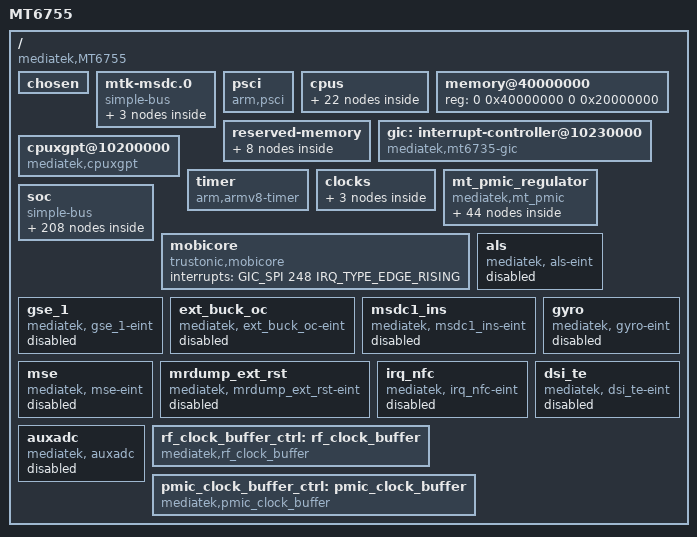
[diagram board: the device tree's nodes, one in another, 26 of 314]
/*
 * Mediatek's MT6755 SoC device tree source
 *
 * Copyright (c) 2013 MediaTek Co., Ltd.
 *              http://www.mediatek.com
 *
 */

#include <dt-bindings/clock/mt6755-clk.h>
#include <dt-bindings/interrupt-controller/arm-gic.h>
#include <dt-bindings/interrupt-controller/irq.h>
#include <dt-bindings/mmc/mt6755-msdc.h>
#include "mt6755-pinfunc.h"
/ {
	model = "MT6755";
	compatible = "mediatek,MT6755";
	interrupt-parent = <&gic>;
	#address-cells = <2>;
	#size-cells = <2>;

	/* chosen */
	chosen {
		bootargs = "console=tty0 console=ttyMT0,921600n1 root=/dev/ram initrd=0x44000000,0x4b434e loglevel=8";
	};

	/* Do not put any bus before mtk-msdc, because it should be mtk-msdc.0 for partition device node usage */
	mtk-msdc.0 {
		compatible = "simple-bus";
		#address-cells = <1>;
		#size-cells = <1>;
		ranges = <0 0 0 0xffffffff>;

		mmc0: msdc0@11230000 {
			compatible = "mediatek,mt6755-mmc";
			reg = <0x11230000 0x10000>;
			interrupts = <GIC_SPI 79 IRQ_TYPE_LEVEL_LOW>;
			clocks = <&infrasys INFRA_MSDC0>;
			clock-names = "MSDC0-CLOCK";
		};

		mmc1: msdc1@11240000 {
			compatible = "mediatek,mt6755-mmc";
			reg = <0x11240000 0x10000>;
			interrupts = <GIC_SPI 80 IRQ_TYPE_LEVEL_LOW>;
			clocks = <&infrasys INFRA_MSDC1>;
			clock-names = "MSDC1-CLOCK";
		};

		mmc2: msdc2@11250000 {
			compatible = "mediatek,mt6755-mmc";
			reg = <0x11250000 0x10000>;
			interrupts = <GIC_SPI 81 IRQ_TYPE_LEVEL_LOW>;
			clocks = <&infrasys INFRA_MSDC2>;
			clock-names = "MSDC2-CLOCK";
		};

		/*
		mmc3: msdc3@11260000 {
			compatible = "mediatek,mt6755-mmc";
			reg = <0x11260000 0x10000>;
			interrupts = <GIC_SPI 82 IRQ_TYPE_LEVEL_LOW>;
			clocks = <&infrasys INFRA_MSDC3>;
			clock-names = "MSDC3-CLOCK";
		};
*/
	};

	psci {
		compatible  = "arm,psci";
		method      = "smc";
		cpu_suspend = <0x84000001>;
		cpu_off     = <0x84000002>;
		cpu_on      = <0x84000003>;
		affinity_info = <0x84000004>;
	};

	cpus {
		#address-cells = <1>;
		#size-cells = <0>;

		cpu0: cpu@000 {
			device_type = "cpu";
			compatible = "arm,cortex-a53";
			reg = <0x000>;
			enable-method = "mt-boot";
			cpu-idle-states = <&cluster_sleep_0 &cluster_sleep_0 &cluster_sleep_0>,
					  <&cpu_sleep_0_0 &cpu_sleep_0_0 &cpu_sleep_0_0>;
			cpu-release-addr = <0x0 0x40000200>;
			clock-frequency = <1144000000>;
		};
		cpu1: cpu@001 {
			device_type = "cpu";
			compatible = "arm,cortex-a53";
			reg = <0x001>;
			enable-method = "mt-boot";
			cpu-idle-states = <&cluster_sleep_0 &cluster_sleep_0 &cluster_sleep_0>,
					  <&cpu_sleep_0_0 &cpu_sleep_0_0 &cpu_sleep_0_0>;
			cpu-release-addr = <0x0 0x40000200>;
			clock-frequency = <1144000000>;
		};

		cpu2: cpu@002 {
			device_type = "cpu";
			compatible = "arm,cortex-a53";
			reg = <0x002>;
			enable-method = "mt-boot";
			cpu-idle-states = <&cluster_sleep_0 &cluster_sleep_0 &cluster_sleep_0>,
					  <&cpu_sleep_0_0 &cpu_sleep_0_0 &cpu_sleep_0_0>;
			cpu-release-addr = <0x0 0x40000200>;
			clock-frequency = <1144000000>;
		};

		cpu3: cpu@003 {
			device_type = "cpu";
			compatible = "arm,cortex-a53";
			reg = <0x003>;
			enable-method = "mt-boot";
			cpu-idle-states = <&cluster_sleep_0 &cluster_sleep_0 &cluster_sleep_0>,
					  <&cpu_sleep_0_0 &cpu_sleep_0_0 &cpu_sleep_0_0>;
			cpu-release-addr = <0x0 0x40000200>;
			clock-frequency = <1144000000>;
		};

		cpu4: cpu@100 {
			device_type = "cpu";
			compatible = "arm,cortex-a53";
			reg = <0x100>;
			enable-method = "mt-boot";
			cpu-idle-states = <&cluster_sleep_0 &cluster_sleep_0 &cluster_sleep_0>,
					  <&cpu_sleep_0_0 &cpu_sleep_0_0 &cpu_sleep_0_0>;
			cpu-release-addr = <0x0 0x40000200>;
			clock-frequency = <1950000000>;
		};

		cpu5: cpu@101 {
			device_type = "cpu";
			compatible = "arm,cortex-a53";
			reg = <0x101>;
			enable-method = "mt-boot";
			cpu-idle-states = <&cluster_sleep_0 &cluster_sleep_0 &cluster_sleep_0>,
					  <&cpu_sleep_0_0 &cpu_sleep_0_0 &cpu_sleep_0_0>;
			cpu-release-addr = <0x0 0x40000200>;
			clock-frequency = <1950000000>;
		};

		cpu6: cpu@102 {
			device_type = "cpu";
			compatible = "arm,cortex-a53";
			reg = <0x102>;
			enable-method = "mt-boot";
			cpu-idle-states = <&cluster_sleep_0 &cluster_sleep_0 &cluster_sleep_0>,
					  <&cpu_sleep_0_0 &cpu_sleep_0_0 &cpu_sleep_0_0>;
			cpu-release-addr = <0x0 0x40000200>;
			clock-frequency = <1950000000>;
		};

		cpu7: cpu@103 {
			device_type = "cpu";
			compatible = "arm,cortex-a53";
			reg = <0x103>;
			enable-method = "mt-boot";
			cpu-idle-states = <&cluster_sleep_0 &cluster_sleep_0 &cluster_sleep_0>,
					  <&cpu_sleep_0_0 &cpu_sleep_0_0 &cpu_sleep_0_0>;
			cpu-release-addr = <0x0 0x40000200>;
			clock-frequency = <1950000000>;

		};

		cpu-map {
			cluster0 {
				core0 {
					cpu = <&cpu0>;
				};
				core1 {
					cpu = <&cpu1>;
				};
				core2 {
					cpu = <&cpu2>;
				};
				core3 {
					cpu = <&cpu3>;
				};
			};

			cluster1 {
				core0 {
					cpu = <&cpu4>;
				};
				core1 {
					cpu = <&cpu5>;
				};
				core2 {
					cpu = <&cpu6>;
				};
				core3 {
					cpu = <&cpu7>;
				};
			};
		};

		idle-states {
			entry-method = "arm,psci";

			cpu_sleep_0_0: cpu-sleep-0-0 {
				compatible = "arm,idle-state";
				arm,psci-suspend-param = <0x0010000>;
				entry-latency-us = <600>;
				exit-latency-us = <600>;
				min-residency-us = <1200>;
			};

			cluster_sleep_0: cluster-sleep-0 {
				compatible = "arm,idle-state";
				arm,psci-suspend-param = <0x1010000>;
				entry-latency-us = <800>;
				exit-latency-us = <1000>;
				min-residency-us = <2000>;
			};
		};
	};

	memory@40000000 {
		device_type = "memory";
		reg = <0 0x40000000 0 0x20000000>;
	};

	reserved-memory {
		#address-cells = <2>;
		#size-cells = <2>;
		ranges;

		/* reserve 192KB at DRAM start + 48MB */
		atf-reserved-memory@43000000 {
			compatible = "mediatek,mt6735-atf-reserved-memory",
				"mediatek,mt6735m-atf-reserved-memory",
				"mediatek,mt6753-atf-reserved-memory";
			no-map;
			reg = <0 0x43000000 0 0x30000>;
		};

		reserve-memory-ccci_md1 {
			compatible = "mediatek,reserve-memory-ccci_md1";
			no-map;
			size = <0 0xA100000>; /* md_size+smem_size */
			alignment = <0 0x2000000>;
			alloc-ranges = <0 0x40000000 0 0xC0000000>;
		};

		consys-reserve-memory {
			compatible = "mediatek,consys-reserve-memory";
			no-map;
			size = <0 0x100000>;
			alignment = <0 0x200000>;
		};

		ram_console-reserved-memory@44400000 {
			compatible = "mediatek,ram_console";
			reg = <0 0x44400000 0 0x10000>;
		};

		preloader-reserved-memory@44800000 {
			compatible = "mediatek,preloader";
			reg = <0 0x44800000 0 0x200000>;
		};

		lk-reserved-memory@46000000 {
			compatible = "mediatek,lk";
			reg = <0 0x46000000 0 0x900000>;
		};

		minirdump-reserved-memory@444f0000 {
			compatible = "mediatek, minirdump";
			reg = <0 0x444f0000 0 0x10000>;
		};

		pstore-reserved-memory@44410000 {
			compatible = "mediatek,pstore";
			reg = <0 0x44410000 0 0xe0000>;
		};

	};

	gic: interrupt-controller@10230000 {
		compatible = "mediatek,mt6735-gic";
		#interrupt-cells = <3>;
		#address-cells = <0>;
		interrupt-controller;
		reg = <0 0x10231000 0 0x1000>,
		      <0 0x10232000 0 0x1000>,
		      <0 0x10200620 0 0x1000>;
	};

	cpuxgpt@10200000 {
		compatible = "mediatek,cpuxgpt";
		reg = <0 0x10200000 0 0x1000>;
		interrupts = <GIC_SPI 64 IRQ_TYPE_LEVEL_HIGH>,
				<GIC_SPI 65 IRQ_TYPE_LEVEL_HIGH>,
				<GIC_SPI 66 IRQ_TYPE_LEVEL_HIGH>,
				<GIC_SPI 67 IRQ_TYPE_LEVEL_HIGH>,
				<GIC_SPI 68 IRQ_TYPE_LEVEL_HIGH>,
				<GIC_SPI 69 IRQ_TYPE_LEVEL_HIGH>,
				<GIC_SPI 70 IRQ_TYPE_LEVEL_HIGH>,
				<GIC_SPI 71 IRQ_TYPE_LEVEL_HIGH>;
	};

	timer {
		compatible = "arm,armv8-timer";
		interrupts = <GIC_PPI 13 IRQ_TYPE_LEVEL_LOW>,
				<GIC_PPI 14 IRQ_TYPE_LEVEL_LOW>,
				<GIC_PPI 11 IRQ_TYPE_LEVEL_LOW>,
				<GIC_PPI 10 IRQ_TYPE_LEVEL_LOW>;
		clock-frequency = <13000000>;
		};

	clocks {
		clk_null: clk_null {
			compatible = "fixed-clock";
			#clock-cells = <0>;
			clock-frequency = <0>;
		};

		clk26m: clk26m {
			compatible = "fixed-clock";
			#clock-cells = <0>;
			clock-frequency = <26000000>;
		};

		clk32k: clk32k {
			compatible = "fixed-clock";
			#clock-cells = <0>;
			clock-frequency = <32000>;
		};
	};

	mt_pmic_regulator {
		compatible = "mediatek,mt_pmic";
		/*reg = <0x01>*/
		buck_regulators {
			compatible = "mediatek,mt_pmic_buck_regulators";
			mt_pmic_vcore_buck_reg: buck_vcore {
				regulator-name = "vcore";
				regulator-min-microvolt = <600000>;
				regulator-max-microvolt = <1393750>;
				regulator-ramp-delay = <6250>;
				regulator-enable-ramp-delay = <180>;
			};
			mt_pmic_vgpu_buck_reg: buck_vgpu {
				regulator-name = "vgpu";
				regulator-min-microvolt = <600000>;
				regulator-max-microvolt = <1393750>;
				regulator-ramp-delay = <6250>;
				regulator-enable-ramp-delay = <180>;
				regulator-always-on;
				regulator-boot-on;
			};
			mt_pmic_vmodem_buck_reg: buck_vmodem {
				regulator-name = "vmodem";
				regulator-min-microvolt = <600000>;
				regulator-max-microvolt = <1393750>;
				regulator-ramp-delay = <6250>;
				regulator-enable-ramp-delay = <180>;
				regulator-always-on;
				regulator-boot-on;
			};
			mt_pmic_vmd1_buck_reg: buck_vmd1 {
				regulator-name = "vmd1";
				regulator-min-microvolt = <600000>;
				regulator-max-microvolt = <1393750>;
				regulator-ramp-delay = <6250>;
				regulator-enable-ramp-delay = <180>;
				regulator-always-on;
				regulator-boot-on;
			};
			mt_pmic_vsram_md_buck_reg: buck_vsram_md {
				regulator-name = "vsram_md";
				regulator-min-microvolt = <600000>;
				regulator-max-microvolt = <1393750>;
				regulator-ramp-delay = <6250>;
				regulator-enable-ramp-delay = <180>;
				regulator-always-on;
				regulator-boot-on;
			};
			mt_pmic_vs1_buck_reg: buck_vs1 {
				regulator-name = "vs1";
				regulator-min-microvolt = <600000>;
				regulator-max-microvolt = <1393750>;
				regulator-ramp-delay = <6250>;
				regulator-enable-ramp-delay = <180>;
				regulator-always-on;
				regulator-boot-on;
			};
			mt_pmic_vs2_buck_reg: buck_vs2 {
				regulator-name = "vs2";
				regulator-min-microvolt = <600000>;
				regulator-max-microvolt = <1393750>;
				regulator-ramp-delay = <6250>;
				regulator-enable-ramp-delay = <180>;
				regulator-always-on;
				regulator-boot-on;
			};
			mt_pmic_vpa_buck_reg: buck_vpa {
				regulator-name = "vpa";
				regulator-min-microvolt = <600000>;
				regulator-max-microvolt = <1393750>;
				regulator-ramp-delay = <6250>;
				regulator-enable-ramp-delay = <180>;
				regulator-always-on;
				regulator-boot-on;
			};
			mt_pmic_vsram_proc_buck_reg: buck_vsram_proc {
				regulator-name = "vsram_proc";
				regulator-min-microvolt = <600000>;
				regulator-max-microvolt = <1393750>;
				regulator-ramp-delay = <6250>;
				regulator-enable-ramp-delay = <180>;
				regulator-always-on;
				regulator-boot-on;
			};
		};	/* End of buck_regulators */
		ldo_regulators {
			compatible = "mediatek,mt_pmic_ldo_regulators";
			mt_pmic_va18_ldo_reg: ldo_va18 {
				regulator-name = "va18";
				regulator-min-microvolt = <1800000>;
				regulator-max-microvolt = <1800000>;
				regulator-enable-ramp-delay = <264>;
				regulator-boot-on;
			};
			mt_pmic_vtcxo24_ldo_reg: ldo_vtcxo24 {
				regulator-name = "vtcxo24";
				regulator-min-microvolt = <1800000>;
				regulator-max-microvolt = <2800000>;
				regulator-enable-ramp-delay = <110>;
				regulator-boot-on;
			};
			mt_pmic_vtcxo28_ldo_reg: ldo_vtcxo28 {
				regulator-name = "vtcxo28";
				regulator-min-microvolt = <1800000>;
				regulator-max-microvolt = <2800000>;
				regulator-enable-ramp-delay = <110>;
			};
			mt_pmic_vcn28_ldo_reg: ldo_vcn28 {
				regulator-name = "vcn28";
				regulator-min-microvolt = <1800000>;
				regulator-max-microvolt = <2800000>;
				regulator-enable-ramp-delay = <264>;
			};
			mt_pmic_vcama_ldo_reg: ldo_vcama {
				regulator-name = "vcama";
				regulator-min-microvolt = <1500000>;
				regulator-max-microvolt = <2800000>;
				regulator-enable-ramp-delay = <264>;
			};
			mt_pmic_vusb33_ldo_reg: ldo_vusb33 {
				regulator-name = "vusb33";
				regulator-min-microvolt = <3300000>;
				regulator-max-microvolt = <3300000>;
				regulator-enable-ramp-delay = <264>;
				regulator-boot-on;
			};
			mt_pmic_vsim1_ldo_reg: ldo_vsim1 {
				regulator-name = "vsim1";
				regulator-min-microvolt = <1700000>;
				regulator-max-microvolt = <3100000>;
				regulator-enable-ramp-delay = <264>;
			};
			mt_pmic_vsim2_ldo_reg: ldo_vsim2 {
				regulator-name = "vsim2";
				regulator-min-microvolt = <1700000>;
				regulator-max-microvolt = <3100000>;
				regulator-enable-ramp-delay = <264>;
			};
			mt_pmic_vemc_ldo_reg: ldo_vemc {
				regulator-name = "vemc_3v3";
				regulator-min-microvolt = <3000000>;
				regulator-max-microvolt = <3300000>;
				regulator-enable-ramp-delay = <44>;
				regulator-boot-on;
			};
			mt_pmic_vmch_ldo_reg: ldo_vmch {
				regulator-name = "vmch";
				regulator-min-microvolt = <3000000>;
				regulator-max-microvolt = <3300000>;
				regulator-enable-ramp-delay = <44>;
				regulator-boot-on;
			};
			mt_pmic_vio28_ldo_reg: ldo_vio28 {
				regulator-name = "vio28";
				regulator-min-microvolt = <2800000>;
				regulator-max-microvolt = <2800000>;
				regulator-enable-ramp-delay = <264>;
				regulator-boot-on;
			};
			mt_pmic_vibr_ldo_reg: ldo_vibr {
				regulator-name = "vibr";
				regulator-min-microvolt = <1200000>;
				regulator-max-microvolt = <3300000>;
				regulator-enable-ramp-delay = <44>;
			};
			mt_pmic_vcamd_ldo_reg: ldo_vcamd {
				regulator-name = "vcamd";
				regulator-min-microvolt = <900000>;
				regulator-max-microvolt = <1210000>;
				regulator-enable-ramp-delay = <264>;
			};
			mt_pmic_vrf18_ldo_reg: ldo_vrf18 {
				regulator-name = "vrf18";
				regulator-min-microvolt = <1000000>;
				regulator-max-microvolt = <1810000>;
				regulator-enable-ramp-delay = <220>;
			};
			mt_pmic_vio18_ldo_reg: ldo_vio18 {
				regulator-name = "vio18";
				regulator-min-microvolt = <1800000>;
				regulator-max-microvolt = <1800000>;
				regulator-enable-ramp-delay = <264>;
				regulator-boot-on;
			};
			mt_pmic_vcn18_ldo_reg: ldo_vcn18 {
				regulator-name = "vcn18";
				regulator-min-microvolt = <1800000>;
				regulator-max-microvolt = <1800000>;
				regulator-enable-ramp-delay = <44>;
			};
			mt_pmic_vcamio_ldo_reg: ldo_vcamio {
				regulator-name = "vcamio";
				regulator-min-microvolt = <1200000>;
				regulator-max-microvolt = <1800000>;
				regulator-enable-ramp-delay = <220>;
			};
			mt_pmic_vsram_proc_ldo_reg: ldo_vsram_proc {
				regulator-name = "vsram_proc";
				regulator-min-microvolt = <600000>;
				regulator-max-microvolt = <1393750>;
				regulator-enable-ramp-delay = <220>;
				regulator-boot-on;
			};
			mt_pmic_vxo22_ldo_reg: ldo_vxo22 {
				regulator-name = "vxo22";
				regulator-min-microvolt = <1800000>;
				regulator-max-microvolt = <2800000>;
				regulator-enable-ramp-delay = <110>;
				regulator-boot-on;
			};
			mt_pmic_vrf12_ldo_reg: ldo_vrf12 {
				regulator-name = "vrf12";
				regulator-min-microvolt = <900000>;
				regulator-max-microvolt = <1200000>;
				regulator-enable-ramp-delay = <220>;
			};
			mt_pmic_va10_ldo_reg: ldo_va10 {
				regulator-name = "va10";
				regulator-min-microvolt = <900000>;
				regulator-max-microvolt = <1800000>;
				regulator-enable-ramp-delay = <264>;
				regulator-boot-on;
			};
			mt_pmic_vdram_ldo_reg: ldo_vdram {
				regulator-name = "vdram";
				regulator-min-microvolt = <900000>;
				regulator-max-microvolt = <1210000>;
				regulator-enable-ramp-delay = <264>;
				regulator-boot-on;
			};
			mt_pmic_vmipi_ldo_reg: ldo_vmipi {
				regulator-name = "vmipi";
				regulator-min-microvolt = <900000>;
				regulator-max-microvolt = <1800000>;
				regulator-enable-ramp-delay = <264>;
			};
			mt_pmic_vgp3_ldo_reg: ldo_vgp3 {
				regulator-name = "vgp3";
				regulator-min-microvolt = <1000000>;
				regulator-max-microvolt = <1810000>;
				regulator-enable-ramp-delay = <264>;
			};
			mt_pmic_vbif28_ldo_reg: ldo_vbif28 {
				regulator-name = "vbif28";
				regulator-min-microvolt = <2800000>;
				regulator-max-microvolt = <2800000>;
				regulator-enable-ramp-delay = <264>;
			};
			mt_pmic_vefuse_ldo_reg: ldo_vefuse {
				regulator-name = "vefuse";
				regulator-min-microvolt = <1200000>;
				regulator-max-microvolt = <2200000>;
				regulator-enable-ramp-delay = <264>;
			};
			mt_pmic_vcn33_bt_ldo_reg: ldo_vcn33_bt {
				regulator-name = "vcn33_bt";
				regulator-min-microvolt = <3300000>;
				regulator-max-microvolt = <3600000>;
				regulator-enable-ramp-delay = <264>;
			};
			mt_pmic_vcn33_wifi_ldo_reg: ldo_vcn33_wifi {
				regulator-name = "vcn33_wifi";
				regulator-min-microvolt = <3300000>;
				regulator-max-microvolt = <3600000>;
				regulator-enable-ramp-delay = <264>;
			};
			mt_pmic_vldo28_ldo_reg: ldo_vldo28 {
				regulator-name = "vldo28";
				regulator-min-microvolt = <2800000>;
				regulator-max-microvolt = <2800000>;
				regulator-enable-ramp-delay = <264>;
			};
			mt_pmic_vmc_ldo_reg: ldo_vmc {
				regulator-name = "vmc";
				regulator-min-microvolt = <1200000>;
				regulator-max-microvolt = <3300000>;
				regulator-enable-ramp-delay = <44>;
				regulator-boot-on;
			};
			mt_pmic_vldo28_0_ldo_reg: ldo_vldo28_0 {
				regulator-name = "vldo28_0";
				regulator-min-microvolt = <2800000>;
				regulator-max-microvolt = <2800000>;
				regulator-enable-ramp-delay = <264>;
			};
			mt_pmic_vldo28_1_ldo_reg: ldo_vldo28_1 {
				regulator-name = "vldo28_1";
				regulator-min-microvolt = <2800000>;
				regulator-max-microvolt = <2800000>;
				regulator-enable-ramp-delay = <264>;
			};
		};/* End of ldo_regulators */

		regulators_supply {
			compatible = "mediatek,mt_pmic_regulator_supply";
			va18-supply = <&mt_pmic_va18_ldo_reg>;
			vtcxo24-supply = <&mt_pmic_vtcxo24_ldo_reg>;
			vtcxo28-supply = <&mt_pmic_vtcxo28_ldo_reg>;
			vsim1-supply = <&mt_pmic_vsim1_ldo_reg>;
			vsim2-supply = <&mt_pmic_vsim2_ldo_reg>;
			vemc-supply = <&mt_pmic_vemc_ldo_reg>;
			vmch-supply = <&mt_pmic_vmch_ldo_reg>;
			vmc-supply = <&mt_pmic_vmc_ldo_reg>;
			vio28-supply = <&mt_pmic_vio28_ldo_reg>;
			vibr-supply = <&mt_pmic_vibr_ldo_reg>;
			vrf18-supply = <&mt_pmic_vrf18_ldo_reg>;
			vio18-supply = <&mt_pmic_vio18_ldo_reg>;
			vsram_proc-supply = <&mt_pmic_vsram_proc_ldo_reg>;
			vxo22-supply = <&mt_pmic_vxo22_ldo_reg>;
			vrf12-supply = <&mt_pmic_vrf12_ldo_reg>;
			vdram-supply = <&mt_pmic_vdram_ldo_reg>;
			vmipi-supply = <&mt_pmic_vmipi_ldo_reg>;
			vbif28-supply = <&mt_pmic_vbif28_ldo_reg>;
			vefuse-supply = <&mt_pmic_vefuse_ldo_reg>;
		};/* End of regulators_supply */
	};/* End of mt_pmic_regulator */

	soc {
		compatible = "simple-bus";
		#address-cells = <1>;
		#size-cells = <1>;
		ranges;

		chipid@08000000 {
			compatible = "mediatek,chipid";
			reg = <0x08000000 0x0004>,
					<0x08000004 0x0004>,
					<0x08000008 0x0004>,
					<0x0800000C 0x0004>;
		};

		topckgen: topckgen@10000000 {
			compatible = "mediatek,mt6755-topckgen", "mediatek,topckgen";
			reg = <0x10000000 0x1000>;
			#clock-cells = <1>;
		};

		infracfg_ao@10001000 {
			compatible = "mediatek,infracfg_ao";
			reg = <0x10001000 0x1000>;
			interrupts = <GIC_SPI 136 IRQ_TYPE_EDGE_RISING>;
		};

		scpsys: scpsys@10001000 {
			compatible = "mediatek,mt6755-scpsys";
			reg = <0x10001000 0x1000>, <0x10006000 0x1000>;
			#clock-cells = <1>;
		};

		infrasys: infrasys@10001000 {
			compatible = "mediatek,mt6755-infrasys";
			reg = <0x10001000 0x1000>;
			#clock-cells = <1>;
		};

		iocfg_0@10002000 {
			compatible = "mediatek,iocfg_0";
			reg = <0x10002000 0x1000>;
		};

		syscfg_pctl_a: syscfg_pctl_a@10002000 {
			compatible = "mediatek,mt6755-pctl-a-syscfg", "syscon";
			reg = <0x10002000 0x1000>;
		};

		iocfg_1@10002200 {
			compatible = "mediatek,iocfg_1";
			reg = <0x10002200 0x200>;
		};

		iocfg_2@10002400 {
			compatible = "mediatek,iocfg_2";
			reg = <0x10002400 0x200>;
		};

		iocfg_3@10002600 {
			compatible = "mediatek,iocfg_3";
			reg = <0x10002600 0x200>;
		};

		iocfg_4@10002800 {
			compatible = "mediatek,iocfg_4";
			reg = <0x10002800 0x200>;
		};

		iocfg_5@10002a00 {
			compatible = "mediatek,iocfg_5";
			reg = <0x10002a00 0x200>;
		};

		perisys: perisys@10003000 {
			compatible = "mediatek,mt6755-perisys";
			reg = <0x10003000 0x1000>;
			#clock-cells = <1>;
		};

		dramc@10004000 {
			compatible = "mediatek,dramc";
			reg = <0x10004000 0x1000>;
			interrupts = <GIC_SPI 149 IRQ_TYPE_EDGE_FALLING>;
		};

		pio: pinctrl@10005000 {
			compatible = "mediatek,mt6755-pinctrl";
			reg = <0x10005000 0x1000>;
			mediatek,pctl-regmap = <&syscfg_pctl_a>;
			pins-are-numbered;
			gpio-controller;
			#gpio-cells = <2>;
		};

		gpio_usage_mapping:gpio {
			compatible = "mediatek,gpio_usage_mapping";
		};

		gpio@10005000 {
			compatible = "mediatek,gpio";
			reg = <0x10005000 0x1000>;
		};

		sleep@10006000 {
			compatible = "mediatek,sleep";
			reg = <0x10006000 0x1000>;
			interrupts = <GIC_SPI 165 IRQ_TYPE_LEVEL_LOW>;
			clocks = <&infrasys INFRA_I2C3>;
			clock-names = "i2c3-main";
			clock-div = <10>;
			#address-cells = <1>;
			#size-cells = <0>;
			eint_spm_vcorefs_start@152 {
				compatible = "mediatek,spm_vcorefs_start_eint";
				interrupt-parent = <&eintc>;
				interrupts = <152 IRQ_TYPE_LEVEL_HIGH>;
				debounce = <152 0>;
			};

			eint_spm_vcorefs_end@153 {
				compatible = "mediatek,spm_vcorefs_end_eint";
				interrupt-parent = <&eintc>;
				interrupts = <153 IRQ_TYPE_LEVEL_HIGH>;
				debounce = <153 0>;
			};

		};

		toprgu@10007000 {
			compatible = "mediatek,toprgu";
			reg = <0x10007000 0x1000>;
			interrupts = <GIC_SPI 128 IRQ_TYPE_EDGE_FALLING>;
		};

		apxgpt@10008000 {
			compatible = "mediatek,apxgpt";
			reg = <0x10008000 0x1000>;
			interrupts = <GIC_SPI 154 IRQ_TYPE_LEVEL_LOW>;
			clock-frequency = <13000000>;
		};

		rsvd@10009000 {
			compatible = "mediatek,rsvd";
			reg = <0x10009000 0x1000>;
		};

		sej@1000a000 {
			compatible = "mediatek,sej";
			reg = <0x1000a000 0x1000>;
			interrupts = <GIC_SPI 173 IRQ_TYPE_LEVEL_LOW>;
			clocks = <&infrasys INFRA_SEJ>;
			clock-names = "sej-main";

		};

		eintc: eintc@1000b000 {
			compatible = "mediatek,mt-eic";
			reg = <0x1000b000 0x1000>;
			interrupts = <GIC_SPI 155 IRQ_TYPE_LEVEL_HIGH>;
			max_deint_cnt = <4>;
			deint_possible_irq = <191 192 193 194>;
			#interrupt-cells = <2>;
			interrupt-controller;
			mediatek,max_eint_num = <160>;
			mediatek,mapping_table_entry = <0>;
		};

		apmixedsys: apmixedsys@1000c000 {
			compatible = "mediatek,mt6755-apmixedsys", "mediatek,apmixed";
			reg = <0x1000c000 0x1000>;
			#clock-cells = <1>;
		};

		fhctl@1000cf00 {
			compatible = "mediatek,fhctl";
			reg = <0x1000cf00 0x100>;
		};

		pwrap: pwrap@1000d000 {
			compatible = "mediatek,pwrap";
			reg = <0x1000d000 0x1000>;
			interrupts = <GIC_SPI 163 IRQ_TYPE_LEVEL_HIGH>;

			pmic: mt6351 {
				compatible = "mediatek,mt6351-pmic";
				interrupt-parent = <&eintc>;
				interrupts = <150 IRQ_TYPE_LEVEL_HIGH>;
				debounce = <150 1000>;
				interrupt-controller;
			};
		};

		devapc_ao@1000e000 {
			compatible = "mediatek,devapc_ao";
			reg = <0x1000e000 0x1000>;
		};

		ddrphy@1000f000 {
			compatible = "mediatek,ddrphy";
			reg = <0x1000f000 0x1000>;
		};

		keypad: keypad@10010000 {
			compatible = "mediatek,mt6755-keypad", "mediatek,kp";
			reg = <0x10010000 0x1000>;
			interrupts = <GIC_SPI 164 IRQ_TYPE_EDGE_FALLING>;
		};

		topmisc@10011000 {
			compatible = "mediatek,topmisc";
			reg = <0x10011000 0x1000>;
		};

		mdcldma:mdcldma@10014800 {
			compatible = "mediatek,mdcldma";
			reg =	<0x10014800 0x1e00>, /*AP_CLDMA_AO*/
				<0x10015800 0x1e00>, /*MD_CLDMA_AO*/
				<0x1021B000 0x1e00>, /*AP_CLDMA_PDN*/
				<0x1021C000 0x1e00>, /*MD_CLDMA_PDN*/
				<0x10209000 0x1000>, /*AP_CCIF_BASE*/
				<0x1020A000 0x1000>; /*MD_CCIF_BASE*/
			interrupts = <GIC_SPI 222 IRQ_TYPE_LEVEL_HIGH>, /*IRQ_CLDMA*/
				     <GIC_SPI 139 IRQ_TYPE_LEVEL_LOW>, /*IRQ_CCIF*/
				     <GIC_SPI 223 IRQ_TYPE_EDGE_FALLING>; /*IRQ_MDWDT*/
			mediatek,md_id = <0>;
			mediatek,cldma_capability = <6>;
			mediatek,md_smem_size = <0x100000>; /* md share memory size */
			clocks = <&scpsys SCP_SYS_MD1>;
			clock-names = "scp-sys-md1-main";
		};

		aes_top0@10016000 {
			compatible = "mediatek,aes_top0";
			reg = <0x10016000 0x1000>;
		};

		aes_top1@10017000 {
			compatible = "mediatek,aes_top1";
			reg = <0x10017000 0x1000>;
		};

		modem_temp_share@10018000 {
			compatible = "mediatek,modem_temp_share";
			reg = <0x10018000 0x1000>;
		};

		scp_sram@10020000 {
			compatible = "mediatek,scp_sram";
			reg = <0x10020000 0x60000>;
		};

		dbgapb_base@1011a000{
			compatible = "mediatek,dbgapb_base";
			reg = <0x1011a000 0x100>;/* MD debug register */
		};

		lastbus@10200000 {
			compatible = "mediatek,lastbus";
			reg = <0x10200000 0x1000>,
				<0x10003000 0x1000>;
		};

		mcucfg@10200000 {
			compatible = "mediatek,mcucfg";
			reg = <0x10200000 0x1000>;
			interrupts = <GIC_SPI 0 IRQ_TYPE_LEVEL_LOW>;
		};

		infracfg@10201000 {
			compatible = "mediatek,infracfg";
			reg = <0x10201000 0x1000>;
		};

		sramrom@10202000 {
			compatible = "mediatek,sramrom";
			reg = <0x10202000 0x1000>;
		};

		emi@10203000 {
			compatible = "mediatek,emi";
			reg = <0x10203000 0x1000>;
			interrupts = <GIC_SPI 135 IRQ_TYPE_EDGE_FALLING>;
		};

		met_emi: met_emi@10203000 {
			compatible = "mediatek,met_emi";
			reg = <0x10203000 0x1000>;
		};

		sys_cirq@10204000 {
			compatible = "mediatek,sys_cirq";
			reg = <0x10204000 0x1000>;
			interrupts = <GIC_SPI 240 IRQ_TYPE_EDGE_FALLING>;
			cirq_num = <168>;
			spi_start_offset = <72>;
		};

		m4u@10205000 {
			cell-index = <0>;
			compatible = "mediatek,m4u";
			reg = <0x10205000 0x1000>;
			interrupts = <GIC_SPI 147 IRQ_TYPE_LEVEL_LOW>;
			clocks = <&mmsys MM_DISP0_SMI_COMMON_M4U>,
				<&mmsys MM_DISP0_SMI_LARB0_M4U>,
				<&vdecsys VDEC0_VDEC>,
				<&vdecsys VDEC1_LARB_M4U>,
				<&imgsys IMG_IMAGE_LARB2_SMI_M4U>,
				<&vencsys VENC_VENC>,
				<&vencsys VENC_LARB_M4U>;
			clock-names = "smi_common",
				"m4u_disp0_smi_larb0",
				"m4u_vdec0_vdec",
				"m4u_vdec1_larb",
				"m4u_img_image_larb2_smi",
				"m4u_venc_venc",
				"m4u_venc_larb";
		};

		efusec@10206000 {
			compatible = "mediatek,efusec";
			reg = <0x10206000 0x1000>;
		};

		devapc@10207000 {
			compatible = "mediatek,devapc";
			reg = <0x10207000 0x1000>;
			interrupts = <GIC_SPI 133 IRQ_TYPE_LEVEL_LOW>;
			clocks = <&infrasys INFRA_DEVICE_APC>;
			clock-names = "devapc-main";
		};

		bus_dbg@10208000 {
			compatible = "mediatek,bus_dbg";
			reg = <0x10208000 0x1000>;
			interrupts = <GIC_SPI 132 IRQ_TYPE_LEVEL_LOW>;
		};

		ap_ccif0@10209000 {
			compatible = "mediatek,ap_ccif0";
			reg = <0x10209000 0x1000>;
			interrupts = <GIC_SPI 139 IRQ_TYPE_LEVEL_LOW>;
		};

		md_ccif0@1020a000 {
			compatible = "mediatek,md_ccif0";
			reg = <0x1020a000 0x1000>;
		};

		ap2c2k_ccif@1020b000 {
			compatible = "mediatek,ap2c2k_ccif";
			reg = <0x1020b000 0x1000>, //CCIF
			<0x10211000 0x300>, // MD1 PCCIF
			<0x10213000 0x300>; // MD3 PCCIF
			interrupts = <GIC_SPI 141 IRQ_TYPE_LEVEL_LOW>, // C2K_CCIF
					<GIC_SPI 220 IRQ_TYPE_EDGE_FALLING>; // C2K_WDT
			cell-index = <2>;
			ccif,major = <169>;
			ccif,minor_base = <0>;
			ccif,capability = <0>;
			mediatek,md_smem_size = <0x400000>; //md share memory size
			clocks = <&scpsys SCP_SYS_MD2>;
			clock-names = "scp-sys-md2-main";
		};

		md_ccif1@1020c000 {
			compatible = "mediatek,md_ccif1";
			reg = <0x1020c000 0x1000>;
		};

		infra_mbist@1020d000 {
			compatible = "mediatek,infra_mbist";
			reg = <0x1020d000 0x1000>;
		};

		dramc_nao@1020e000 {
			compatible = "mediatek,dramc_nao";
			reg = <0x1020e000 0x1000>;
		};

		met_dramc_nao: met_dramc_nao@1020e000 {
			compatible = "mediatek,met_dramc_nao";
			reg = <0x1020e000 0x1000>;
		};

		trng@1020f000 {
			compatible = "mediatek,trng";
			reg = <0x1020f000 0x1000>;
			interrupts = <GIC_SPI 140 IRQ_TYPE_LEVEL_LOW>;
		};

		gcpu@10210000 {
			compatible = "mediatek,gcpu";
			reg = <0x10210000 0x1000>;
			interrupts = <GIC_SPI 150 IRQ_TYPE_LEVEL_LOW>;
		};

		md2md_md1_ccif0@10211000 {
			compatible = "mediatek,md2md_md1_ccif0";
			reg = <0x10211000 0x1000>;
		};

		gce@10212000 {
			compatible = "mediatek,gce";
			reg = <0x10212000 0x1000>;
			interrupts = <GIC_SPI 143 IRQ_TYPE_LEVEL_LOW>,
					<GIC_SPI 144 IRQ_TYPE_LEVEL_LOW>;
			disp_mutex_reg = <0x14014000 0x1000>;
			g3d_config_base = <0x13000000 0 0xffff0000>;
			mmsys_config_base = <0x14000000 1 0xffff0000>;
			disp_dither_base = <0x14010000 2 0xffff0000>;
			mm_na_base = <0x14020000 3 0xffff0000>;
			imgsys_base = <0x15000000 4 0xffff0000>;
			vdec_gcon_base = <0x16000000 5 0xffff0000>;
			venc_gcon_base = <0x17000000 6 0xffff0000>;
			conn_peri_base = <0x18000000 7 0xffff0000>;
			topckgen_base = <0x10000000 8 0xffff0000>;
			kp_base = <0x10010000 9 0xffff0000>;
			scp_sram_base = <0x10020000 10 0xffff0000>;
			infra_na3_base = <0x10030000 11 0xffff0000>;
			infra_na4_base = <0x10040000 12 0xffff0000>;
			scp_base = <0x10050000 13 0xffff0000>;
			mcucfg_base = <0x10200000 14 0xffff0000>;
			gcpu_base = <0x10210000 15 0xffff0000>;
			usb0_base = <0x11200000 16 0xffff0000>;
			usb_sif_base = <0x11210000 17 0xffff0000>;
			audio_base = <0x11220000 18 0xffff0000>;
			msdc0_base = <0x11230000 19 0xffff0000>;
			msdc1_base = <0x11240000 20 0xffff0000>;
			msdc2_base = <0x11250000 21 0xffff0000>;
			msdc3_base = <0x11260000 22 0xffff0000>;
			ap_dma_base = <0x11000000 23 0xffff0000>;
			mdp_rdma0_sof = <0>;
			mdp_rsz0_sof = <1>;
			mdp_rsz1_sof = <2>;
			mdp_tdshp_sof = <3>;
			mdp_wdma_sof = <4>;
			mdp_wrot_sof = <5>;
			mdp_color_sof = <6>;
			disp_ovl0_sof = <7>;
			disp_ovl1_sof = <8>;
			disp_rdma0_sof = <9>;
			disp_rdma1_sof = <10>;
			disp_wdma0_sof = <11>;
			disp_color_sof = <12>;
			disp_ccorr_sof = <13>;
			disp_aal_sof = <14>;
			disp_gamma_sof = <15>;
			disp_dither_sof = <16>;
			disp_wdma1_sof = <17>;
			disp_pwm0_sof = <18>;
			disp_2l_ovl0_sof = <19>;
			disp_2l_ovl1_sof = <20>;
			mdp_rdma0_frame_done = <21>;
			mdp_rsz0_frame_done = <22>;
			mdp_rsz1_frame_done = <23>;
			mdp_tdshp_frame_done = <24>;
			mdp_wdma_frame_done = <25>;
			mdp_wrot_write_frame_done = <26>;
			mdp_wrot_read_frame_done = <27>;
			mdp_color_frame_done = <28>;
			disp_ovl0_frame_done = <29>;
			disp_ovl1_frame_done = <30>;
			disp_rdma0_frame_done = <31>;
			disp_rdma1_frame_done = <32>;
			disp_wdma0_frame_done = <33>;
			disp_color_frame_done = <34>;
			disp_ccorr_frame_done = <35>;
			disp_aal_frame_done = <36>;
			disp_gamma_frame_done = <37>;
			disp_dither_frame_done = <38>;
			disp_dpi0_frame_done = <39>;
			disp_wdma1_frame_done = <40>;
			disp_dsi0_frame_done = <41>;
			disp_2l_ovl0_frame_done = <42>;
			disp_2l_ovl1_frame_done = <43>;
			stream_done_0 = <44>;
			stream_done_1 = <45>;
			stream_done_2 = <46>;
			stream_done_3 = <47>;
			stream_done_4 = <48>;
			stream_done_5 = <49>;
			stream_done_6 = <50>;
			stream_done_7 = <51>;
			stream_done_8 = <52>;
			stream_done_9 = <53>;
			buf_underrun_event_0 = <54>;
			buf_underrun_event_1 = <55>;
			dsi0_te_event = <56>;
			isp_frame_done_p2_2 = <129>;
			isp_frame_done_p2_1 = <130>;
			isp_frame_done_p2_0 = <131>;
			isp_frame_done_p1_1 = <132>;
			isp_frame_done_p1_0 = <133>;
			camsv_2_pass1_done = <134>;
			camsv_1_pass1_done = <135>;
			seninf_cam1_2_3_fifo_full = <136>;
			seninf_cam0_fifo_full = <137>;
			venc_done = <257>;
			jpgenc_done = <258>;
			jpgdec_done = <259>;
			venc_mb_done = <260>;
			venc_128byte_cnt_done = <261>;
			apxgpt2_count = <0x10008028>;
			clocks = <&infrasys INFRA_GCE>;
			clock-names = "GCE";
		};

		cqdma: cqdma@10212c00 {
			compatible = "mediatek,mt-cqdma-v1";
			reg = <0x10212c00 0x100>,
			      <0x10212d00 0x100>;
			interrupts = <GIC_SPI 113 IRQ_TYPE_LEVEL_LOW>,
				     <GIC_SPI 114 IRQ_TYPE_LEVEL_LOW>;
			nr_channel = <2>;
		};

		md2md_md2_ccif0@10213000 {
			compatible = "mediatek,md2md_md2_ccif0";
			reg = <0x10213000 0x1000>;
		};

		mipi_tx0@10215000 {
			compatible = "mediatek,mipi_tx0";
			reg = <0x10215000 0x1000>;
		};

		mipi_rx_ana_csi0@10217000 {
			compatible = "mediatek,mipi_rx_ana_csi0";
			reg = <0x10217000 0x1000>;
		};

		mipi_rx_ana_csi1@10218000 {
			compatible = "mediatek,mipi_rx_ana_csi1";
			reg = <0x10218000 0x1000>;
		};

		gcpu_rsa@1021a000 {
			compatible = "mediatek,gcpu_rsa";
			reg = <0x1021a000 0x1000>;
		};

		infra_md@1021d000 {
			compatible = "mediatek,infra_md";
			reg = <0x1021d000 0x1000>;
		};

		bpi_bsi_slv0@1021e000 {
			compatible = "mediatek,bpi_bsi_slv0";
			reg = <0x1021e000 0x1000>;
		};

		bpi_bsi_slv1@1021f000 {
			compatible = "mediatek,bpi_bsi_slv1";
			reg = <0x1021f000 0x6000>;
		};

		bpi_bsi_slv2@10225000 {
			compatible = "mediatek,bpi_bsi_slv2";
			reg = <0x10225000 0x1000>;
		};

		emi_mpu@10226000 {
			compatible = "mediatek,emi_mpu";
			reg = <0x10226000 0x1000>;
			interrupts = <GIC_SPI 117 IRQ_TYPE_LEVEL_HIGH>;
		};

		dvfsp@10227000 {
			compatible = "mediatek,mt6755-dvfsp";
			reg = <0x10227000 0x1000>,
			      <0x0011c000 0xf80>;
			interrupts = <GIC_SPI 152 IRQ_TYPE_LEVEL_LOW>;
			clocks = <&infrasys INFRA_I2C3>;
			clock-names = "i2c";
		};

		met_cci400@10390000 {
			compatible = "mediatek,met_cci400";
			reg = <0x10390000 0x10000>;
		};

		dbgapb@10400000 {
			compatible = "mediatek,dbgapb";
			reg = <0x10400000 0xc00000>;
			interrupts = <GIC_SPI 131 IRQ_TYPE_LEVEL_LOW>;
		};

		ap_dma@11000000 {
			compatible = "mediatek,ap_dma";
			reg = <0x11000000 0x1000>;
			interrupts = <GIC_SPI 97 IRQ_TYPE_LEVEL_LOW>;
		};

		btif_tx: btif_tx@11000780 {
			compatible = "mediatek,btif_tx";
			reg = <0x11000780 0x80>;
			interrupts = <GIC_SPI 111 IRQ_TYPE_LEVEL_LOW>;
		};

		btif_rx: btif_rx@11000800 {
			compatible = "mediatek,btif_rx";
			reg = <0x11000800 0x80>;
			interrupts = <GIC_SPI 116 IRQ_TYPE_LEVEL_LOW>;
		};

		auxadc@11001000 {
			compatible = "mediatek,auxadc";
			reg = <0x11001000 0x1000>;
			interrupts = <GIC_SPI 74 IRQ_TYPE_EDGE_FALLING>;
		};

		apuart0: apuart0@11002000 {
			cell-index = <0>;
			compatible = "mediatek,mt6755-uart";
			reg = <0x11002000 0x1000>, /* UART base */
				  <0x11000380 0x1000>, /* DMA Tx base */
				  <0x11000400 0x80>; /* DMA Rx base */
			interrupts = <GIC_SPI 91 IRQ_TYPE_LEVEL_LOW>, /* UART IRQ */
						 <GIC_SPI 103 IRQ_TYPE_LEVEL_LOW>, /* DMA Tx IRQ */
						 <GIC_SPI 104 IRQ_TYPE_LEVEL_LOW>; /* DMA Rx IRQ */

			clock-frequency = <26000000>;
			clock-div = <1>;
			clocks = <&infrasys INFRA_UART0>, <&infrasys INFRA_AP_DMA>;
			clock-names = "uart0-main", "uart-apdma";
		};

		apuart1: apuart1@11003000 {
			cell-index = <1>;
			compatible = "mediatek,mt6755-uart";
			reg = <0x11003000 0x1000>, /* UART base */
				  <0x11000480 0x80>, /* DMA Tx base */
				  <0x11000500 0x80>; /* DMA Rx base */
			interrupts = <GIC_SPI 92 IRQ_TYPE_LEVEL_LOW>, /* UART IRQ */
						 <GIC_SPI 105 IRQ_TYPE_LEVEL_LOW>, /* DMA Tx IRQ */
						 <GIC_SPI 106 IRQ_TYPE_LEVEL_LOW>; /* DMA Rx IRQ */

			clock-frequency = <26000000>;
			clock-div = <1>;
			clocks = <&infrasys INFRA_UART1>;
			clock-names = "uart1-main";
		};

		pwm: pwm@11006000 {
			compatible = "mediatek,pwm";
			reg = <0x11006000 0x1000>;
			interrupts = <GIC_SPI 77 IRQ_TYPE_LEVEL_LOW>;
			clocks = <&infrasys INFRA_PWM1>,
					 <&infrasys INFRA_PWM2>,
					 <&infrasys INFRA_PWM3>,
					 <&infrasys INFRA_PWM4>,
					 <&infrasys INFRA_PWM_HCLK>,
					 <&infrasys INFRA_PWM>;
			clock-names = "PWM1-main",
						  "PWM2-main",
						  "PWM3-main",
						  "PWM4-main",
						  "PWM-HCLK-main",
						  "PWM-main";
		};

		i2c0: i2c@11007000 {
			compatible = "mediatek,mt6755-i2c", "mediatek,i2c0";
			cell-index = <0>;
			reg = <0x11007000 0x1000>,
			      <0x11000100 0x80>;
			interrupts = <GIC_SPI 84 IRQ_TYPE_LEVEL_LOW>;
			clock-div = <10>;
			clocks = <&infrasys INFRA_I2C0>, <&infrasys INFRA_AP_DMA>;
			clock-names = "main", "dma";
			#address-cells = <1>;
			#size-cells = <0>;
		};

		i2c1: i2c@11008000 {
			compatible = "mediatek,mt6755-i2c", "mediatek,i2c1";
			cell-index = <1>;
			reg = <0x11008000 0x1000>,
			      <0x11000180 0x80>;
			interrupts = <GIC_SPI 85 IRQ_TYPE_LEVEL_LOW>;
			clock-div = <10>;
			clocks = <&infrasys INFRA_I2C1>, <&infrasys INFRA_AP_DMA>;
			clock-names = "main", "dma";
			#address-cells = <1>;
			#size-cells = <0>;
		};

		i2c2: i2c@11009000 {
			compatible = "mediatek,mt6755-i2c", "mediatek,i2c2";
			cell-index = <2>;
			reg = <0x11009000 0x1000>,
			      <0x11000200 0x80>;
			interrupts = <GIC_SPI 86 IRQ_TYPE_LEVEL_LOW>;
			clock-div = <10>;
			clocks = <&infrasys INFRA_I2C2>, <&infrasys INFRA_AP_DMA>;
			clock-names = "main", "dma";
			#address-cells = <1>;
			#size-cells = <0>;
		};

		spi1@1100a000 {
			compatible = "mediatek,spi1";
			reg = <0x1100a000 0x1000>;
			interrupts = <GIC_SPI 118 IRQ_TYPE_LEVEL_LOW>;
			clocks = <&infrasys INFRA_SPI0>;
			clock-names = "spi1-main";
			clock-frequency = <13600>;
			clock-div = <1>;
		};

		therm_ctrl@1100b000 {
			compatible = "mediatek,mt6755-therm_ctrl";
			reg = <0x1100b000 0x1000>;
			interrupts = <GIC_SPI 78 IRQ_TYPE_LEVEL_LOW>;
			clocks = <&infrasys INFRA_THERM>;
			clock-names = "therm-main";
		};

		btif: btif@1100c000 {
			compatible = "mediatek,btif";
			reg = <0x1100c000 0x1000>;
			interrupts = <GIC_SPI 112 IRQ_TYPE_LEVEL_LOW>;
			clocks = <&infrasys INFRA_BTIF>,<&infrasys INFRA_AP_DMA>;
			clock-names = "btifc","apdmac";
		};

		apirtx:irtx@1100d000 {
			compatible = "mediatek,irtx";
			reg = <0x1100d000 0x1000>;
			interrupts = <GIC_SPI 127 IRQ_TYPE_LEVEL_LOW>;
			pwm_ch = <3>;

			clock-frequency = <26000000>;
			clock-div = <1>;
			clocks = <&infrasys INFRA_IRTX>;
			clock-names = "clk-irtx-main";
		};

		disp_pwm@1100e000 {
			compatible = "mediatek,disp_pwm";
			reg = <0x1100e000 0x1000>;
		};

		i2c_appm: i2c@1100f000 {
			compatible = "mediatek,mt6755-i2c", "mediatek,i2c3";
			cell-index = <3>;
			reg = <0x1100f000 0x1000>,
			      <0x11000280 0x80>;
			interrupts = <GIC_SPI 87 IRQ_TYPE_LEVEL_LOW>;
			clock-div = <10>;
			clocks = <&infrasys INFRA_I2C3>, <&infrasys INFRA_AP_DMA>;
			clock-names = "main", "dma";
			#address-cells = <1>;
			#size-cells = <0>;

			mt6311@6b {
				compatible = "mediatek,ext_buck";
				reg = <0x6b>;
			};
		};

		spi2@11010000 {
			compatible = "mediatek,spi2";
			reg = <0x11010000 0x1000>;
			interrupts = <GIC_SPI 122 IRQ_TYPE_LEVEL_LOW>;
		};

		i2c3: i2c@11011000 {
			compatible = "mediatek,mt6755-i2c", "mediatek,i2c4";
			cell-index = <4>;
			reg = <0x11011000 0x1000>,
			      <0x11000300 0x80>;
			interrupts = <GIC_SPI 88 IRQ_TYPE_LEVEL_LOW>;
			clock-div = <10>;
			clocks = <&infrasys INFRA_I2C4>, <&infrasys INFRA_AP_DMA>;
			clock-names = "main", "dma";
			#address-cells = <1>;
			#size-cells = <0>;
		};

		usb1p@11200000 {
			compatible = "mediatek,usb1p";
			reg = <0x11200000 0x10000>;
			interrupts = <GIC_SPI 73 IRQ_TYPE_LEVEL_LOW>;
		};

		usb1p_sif@11210000 {
			compatible = "mediatek,usb1p_sif";
			reg = <0x11210000 0x10000>;
		};

		audiosys: audiosys@11220000 {
			compatible = "mediatek,mt6755-audiosys";
			reg = <0x11220000 0x10000>;
			#clock-cells = <1>;
		};

		audgpio: mt_soc_dl1_pcm@11220000 {
			compatible = "mediatek,mt_soc_pcm_dl1";
			reg = <0x11220000 0x1000>;
			interrupts = <GIC_SPI 142 IRQ_TYPE_LEVEL_LOW>;
			clocks = <&audiosys AUDIO_AFE>,
				<&audiosys AUDIO_I2S>,
				<&audiosys AUDIO_DAC>,
				<&audiosys AUDIO_DAC_PREDIS>,
				<&audiosys AUDIO_ADC>,
				<&audiosys AUDIO_22M>,
				<&audiosys AUDIO_24M>,
				<&audiosys AUDIO_APLL_TUNER>,
				<&audiosys AUDIO_APLL2_TUNER>,
				<&audiosys AUDIO_TML>,
				<&audiosys AUDIO_APLL1_DIV0>,
				<&audiosys AUDIO_APLL2_DIV0>,
				<&scpsys SCP_SYS_AUD>,
				<&infrasys INFRA_AUDIO>,
				<&infrasys INFRA_AUDIO_26M_BCLK>,
				<&topckgen TOP_MUX_AUD1>,
				<&topckgen TOP_MUX_AUD2>,
				<&topckgen TOP_AD_APLL1_CK>,
				<&topckgen TOP_AD_APLL2_CK>,
				<&topckgen TOP_MUX_AUDINTBUS>,
				<&topckgen TOP_SYSPLL1_D4>,
				<&apmixedsys APMIXED_APLL1>,
				<&apmixedsys APMIXED_APLL2>,
				<&clk26m>;
			clock-names = "aud_afe_clk",
				"aud_i2s_clk",
				"aud_dac_clk",
				"aud_dac_predis_clk",
				"aud_adc_clk",
				"aud_apll22m_clk",
				"aud_apll24m_clk",
				"aud_apll1_tuner_clk",
				"aud_apll2_tuner_clk",
				"aud_tml_clk",
				"aud_apll1_div0_clk",
				"aud_apll2_div0_clk",
				"scp_sys_aud",
				"aud_infra_clk",
				"aud_peri_26m_clk",
				"aud_mux1_clk",
				"aud_mux2_clk",
				"top_ad_apll1_clk",
				"top_ad_apll2_clk",
				"top_mux_audio_int",
				"top_sys_pll1_d4",
				"apmixed_apll1_clk",
				"apmixed_apll2_clk",
				"top_clk26m_clk";
		};

		mt_soc_ul1_pcm@11220000 {
			compatible = "mediatek,mt_soc_pcm_capture";
		};

		mt_soc_voice_md1@11220000 {
			compatible = "mediatek,mt_soc_pcm_voice_md1";
		};

		mt_soc_hdmi_pcm@11220000 {
			compatible = "mediatek,mt_soc_pcm_hdmi";
		};

		mt_soc_uldlloopback_pcm@11220000 {
			compatible = "mediatek,mt_soc_pcm_uldlloopback";
		};

		mt_soc_i2s0_pcm@11220000 {
			compatible = "mediatek,mt_soc_pcm_dl1_i2s0";
		};

		mt_soc_mrgrx_pcm@11220000 {
			compatible = "mediatek,mt_soc_pcm_mrgrx";
		};

		mt_soc_mrgrx_awb_pcm@11220000 {
			compatible = "mediatek,mt_soc_pcm_mrgrx_awb";
		};

		mt_soc_fm_i2s_pcm@11220000 {
			compatible = "mediatek,mt_soc_pcm_fm_i2s";
		};

		mt_soc_fm_i2s_awb_pcm@11220000 {
			compatible = "mediatek,mt_soc_pcm_fm_i2s_awb";
		};

		mt_soc_i2s0dl1_pcm@11220000 {
			compatible = "mediatek,mt_soc_pcm_dl1_i2s0Dl1";
		};

		mt_soc_dl1_awb_pcm@11220000 {
			compatible = "mediatek,mt_soc_pcm_dl1_awb";
		};

		mt_soc_voice_md1_bt@11220000 {
			compatible = "mediatek,mt_soc_pcm_voice_md1_bt";
		};

		mt_soc_voip_bt_out@11220000 {
			compatible = "mediatek,mt_soc_pcm_dl1_bt";
		};

		mt_soc_voip_bt_in@11220000 {
			compatible = "mediatek,mt_soc_pcm_bt_dai";
		};

		mt_soc_tdmrx_pcm@11220000 {
			compatible = "mediatek,mt_soc_tdm_capture";
		};

		mt_soc_fm_mrgtx_pcm@11220000 {
			compatible = "mediatek,mt_soc_pcm_fmtx";
		};

		mt_soc_ul2_pcm@11220000 {
			compatible = "mediatek,mt_soc_pcm_capture2";
		};

		mt_soc_i2s0_awb_pcm@11220000 {
			compatible = "mediatek,mt_soc_pcm_i2s0_awb";
		};

		mt_soc_voice_md2@11220000 {
			compatible = "mediatek,mt_soc_pcm_voice_md2";
		};

		mt_soc_routing_pcm@11220000 {
			compatible = "mediatek,mt_soc_pcm_routing";
			i2s1clk-gpio = <7 6>;
			i2s1dat-gpio = <5 6>;
			i2s1mclk-gpio = <9 6>;
			i2s1ws-gpio = <6 6>;
		};

		mt_soc_voice_md2_bt@11220000 {
			compatible = "mediatek,mt_soc_pcm_voice_md2_bt";
		};

		mt_soc_hp_impedance_pcm@11220000 {
			compatible = "mediatek,Mt_soc_pcm_hp_impedance";
		};

		mt_soc_codec_name@11220000 {
			compatible = "mediatek,mt_soc_codec_63xx";
		};

		mt_soc_dummy_pcm@11220000 {
			compatible = "mediatek,mt_soc_pcm_dummy";
		};

		mt_soc_codec_dummy_name@11220000 {
			compatible = "mediatek,mt_soc_codec_dummy";
		};

		mt_soc_routing_dai_name@11220000 {
			compatible = "mediatek,mt_soc_dai_routing";
		};

		mt_soc_dai_name@11220000 {
			compatible = "mediatek,mt_soc_dai_stub";
		};

		mt_soc_offload_gdma@11220000 {
			compatible = "mediatek,mt_soc_pcm_offload_gdma";
		};

		mt_soc_dl2_pcm@11220000 {
			compatible = "mediatek,mt_soc_pcm_dl2";
		};

		icusb@11270000 {
			compatible = "mediatek,icusb";
			reg = <0x11270000 0x10000>;
		};

		usb0p@11270000 {
			compatible = "mediatek,usb0p";
			reg = <0x11270000 0x10000>;
			interrupts = <GIC_SPI 72 IRQ_TYPE_LEVEL_LOW>;
		};

		usbphy0:usbphy@0 {
			 compatible = "usb-nop-xceiv";
		};

		usb3@11270000 {
			compatible = "mediatek,usb3";
			reg = <0x11270000 0x10000>, <0x11280000 0x10000>, <0x11290000 0x10000>;
			reg-names = "ssusb_base", "ssusb_sif", "ssusb_sif2";
			interrupts = <GIC_SPI 72 IRQ_TYPE_LEVEL_LOW>,
					<GIC_SPI 73 IRQ_TYPE_LEVEL_LOW>;
			interrupt-names = "musb-hdrc", "xhci";
		};

		usb3_xhci@11270000 {
			compatible = "mediatek,usb3_xhci";
			reg = <0x11270000 0x10000>, <0x11280000 0x10000>, <0x11290000 0x10000>;
			reg-names = "ssusb_base", "ssusb_sif", "ssusb_sif2";
			interrupts = <GIC_SPI 73 IRQ_TYPE_LEVEL_LOW>;
			iddig-gpio-num = <16>;
			interrupt-names = "xhci";
		};

		usb0p_sif@11280000 {
			compatible = "mediatek,usb0p_sif";
			reg = <0x11280000 0x10000>;
		};

		usb3_sif@11280000 {
			compatible = "mediatek,usb3_sif";
			reg = <0x11280000 0x10000>;
		};

		usb0p_sif2@11290000 {
			compatible = "mediatek,usb0p_sif2";
			reg = <0x11290000 0x10000>;
		};

		usb3_sif2@11290000 {
			compatible = "mediatek,usb3_sif2";
			reg = <0x11290000 0x10000>;
		};

		mfgsys: mfgsys@13000000 {
			compatible = "mediatek,mt6755-mfgsys";
			reg = <0x13000000 0x1000>;
			#clock-cells = <1>;
		};

		mfgcfg@13000000 {
			compatible = "mediatek,mfgcfg";
			reg = <0x13000000 0x1000>;
		};

		mfg_vad@13001000 {
			compatible = "mediatek,mfg_vad";
			reg = <0x13001000 0x1000>;
		};

		mfg_dfp@13020000 {
			compatible = "mediatek,mfg_dfp";
			reg = <0x13020000 0x1000>;
		};

		mali:mali@13040000 {
			compatible = "arm,malit860", "arm,mali-t86x", "arm,malit8xx", "arm,mali-midgard";
			reg = <0x13040000 0x4000>;
			interrupts = <GIC_SPI 218 IRQ_TYPE_LEVEL_LOW>,
					<GIC_SPI 217 IRQ_TYPE_LEVEL_LOW>,
					<GIC_SPI 216 IRQ_TYPE_LEVEL_LOW>;
			interrupt-names = "JOB", "MMU", "GPU";
			clock-frequency = <700000000>;
			clocks = <&mfgsys MFG_BG3D>, <&mmsys MM_DISP0_SMI_COMMON_MALI>,
				<&scpsys SCP_SYS_MFG>, <&scpsys SCP_SYS_DIS>;
			clock-names = "mfg-main", "mfg-smi-common", "mtcmos-mfg", "mtcmos-display";
		};


		mmsys: mmsys_config@14000000 {
			compatible = "mediatek,mmsys_config", "mediatek,mt6755-mmsys";
			reg = <0x14000000 0x1000>;
			interrupts = <GIC_SPI 196 IRQ_TYPE_LEVEL_LOW>;
			clocks = <&mmsys MM_DISP0_CAM_MDP>;
			clock-names = "CAM_MDP";
			#clock-cells = <1>;
		};

		mdp_rdma@14001000 {
			compatible = "mediatek,mdp_rdma";
			reg = <0x14001000 0x1000>;
			interrupts = <GIC_SPI 178 IRQ_TYPE_LEVEL_LOW>;
			clocks = <&mmsys MM_DISP0_MDP_RDMA>;
			clock-names = "MDP_RDMA";
		};

		mdp_rsz0@14002000 {
			compatible = "mediatek,mdp_rsz0";
			reg = <0x14002000 0x1000>;
			interrupts = <GIC_SPI 179 IRQ_TYPE_LEVEL_LOW>;
			clocks = <&mmsys MM_DISP0_MDP_RSZ0>;
			clock-names = "MDP_RSZ0";
		};

		mdp_rsz1@14003000 {
			compatible = "mediatek,mdp_rsz1";
			reg = <0x14003000 0x1000>;
			interrupts = <GIC_SPI 180 IRQ_TYPE_LEVEL_LOW>;
			clocks = <&mmsys MM_DISP0_MDP_RSZ1>;
			clock-names = "MDP_RSZ1";
		};

		mdp_wdma@14004000 {
			compatible = "mediatek,mdp_wdma";
			reg = <0x14004000 0x1000>;
			interrupts = <GIC_SPI 182 IRQ_TYPE_LEVEL_LOW>;
			clocks = <&mmsys MM_DISP0_MDP_WDMA>;
			clock-names = "MDP_WDMA";
		};

		mdp_wrot@14005000 {
			compatible = "mediatek,mdp_wrot";
			reg = <0x14005000 0x1000>;
			interrupts = <GIC_SPI 183 IRQ_TYPE_LEVEL_LOW>;
			clocks = <&mmsys MM_DISP0_MDP_WROT>;
			clock-names = "MDP_WROT";
		};

		mdp_tdshp@14006000 {
			compatible = "mediatek,mdp_tdshp";
			reg = <0x14006000 0x1000>;
			interrupts = <GIC_SPI 181 IRQ_TYPE_LEVEL_LOW>;
			clocks = <&mmsys MM_DISP0_MDP_TDSHP>;
			clock-names = "MDP_TDSHP";
		};

		mdp_color@14007000 {
			compatible = "mediatek,mdp_color";
			reg = <0x14007000 0x1000>;
			interrupts = <GIC_SPI 198 IRQ_TYPE_LEVEL_LOW>;
			clocks = <&mmsys MM_DISP0_MDP_COLOR>;
			clock-names = "MDP_COLOR";
		};

		dispsys@14008000 {
			compatible = "mediatek,dispsys";
			reg = <0x14000000 0x1000>,  /*DISP_SYS     */
			      <0x14008000 0x1000>,  /*DISP_OVL0     */
			      <0x14009000 0x1000>,  /*DISP_OVL1     */
			      <0x1400A000 0x1000>,  /*DISP_RDMA0     */
			      <0x1400B000 0x1000>,  /*DISP_RDMA1     */
			      <0x1400C000 0x1000>,  /*DISP_WDMA0     */
			      <0x1400D000 0x1000>,  /*DISP_COLOR     */
			      <0x1400E000 0x1000>,  /*DISP_CCORR     */
			      <0x1400F000 0x1000>,  /*DISP_AAL       */
			      <0x14010000 0x1000>,  /*DISP_GAMMA     */
			      <0x14011000 0x1000>,  /*DISP_DITHER    */
			      <0x14012000 0x1000>,  /*DISP_DSI0       */
			      <0x14013000 0x1000>,  /*DISP_DPI0      */
			      <0x1100E000 0x1000>,  /*DISP_PWM       */
			      <0x14014000 0x1000>,  /*DISP_MUTEX     */
			      <0x14015000 0x1000>,  /*DISP_SMI_LARB0 */
			      <0x14016000 0x1000>,  /*DISP_SMI_COMMOM*/
			      <0x14017000 0x1000>,  /*DISP_WDMA1*/
			      <0x14018000 0x1000>,  /*DISP_OVL0_2L*/
			      <0x14019000 0x1000>,  /*DISP_OVL1_2L*/
			      <0x10215000 0x1000>;      /*MIPITX0,real chip would use this:<0x14018000 0x1000>;*/


			interrupts = <GIC_SPI 0 IRQ_TYPE_LEVEL_LOW>, /*DISP_SYS */
					<GIC_SPI 184 IRQ_TYPE_LEVEL_LOW>, /*DISP_OVL0 */
					<GIC_SPI 185 IRQ_TYPE_LEVEL_LOW>, /*DISP_OVL1 */
					<GIC_SPI 186 IRQ_TYPE_LEVEL_LOW>, /*DISP_RDMA0 */
					<GIC_SPI 187 IRQ_TYPE_LEVEL_LOW>, /*DISP_RDMA1 */
					<GIC_SPI 188 IRQ_TYPE_LEVEL_LOW>, /*DISP_WDMA0 */
					<GIC_SPI 189 IRQ_TYPE_LEVEL_LOW>, /*DISP_COLOR */
					<GIC_SPI 190 IRQ_TYPE_LEVEL_LOW>, /*DISP_CCORR */
					<GIC_SPI 191 IRQ_TYPE_LEVEL_LOW>, /*DISP_AAL */
					<GIC_SPI 192 IRQ_TYPE_LEVEL_LOW>, /*DISP_GAMMA */
					<GIC_SPI 193 IRQ_TYPE_LEVEL_LOW>, /*DISP_DITHER */
					<GIC_SPI 194 IRQ_TYPE_LEVEL_LOW>, /*DISP_DSI0 */
					<GIC_SPI 195 IRQ_TYPE_LEVEL_LOW>, /*DISP_DPI0 */
					<GIC_SPI 0 IRQ_TYPE_LEVEL_LOW>, /*DISP_PWM */
					<GIC_SPI 177 IRQ_TYPE_LEVEL_LOW>, /*DISP_MUTEX */
					<GIC_SPI 0 IRQ_TYPE_LEVEL_LOW>, /*DISP_SMI_LARB0 */
					<GIC_SPI 0 IRQ_TYPE_LEVEL_LOW>, /*DISP_SMI_COMMOM*/
					<GIC_SPI 197 IRQ_TYPE_LEVEL_LOW>, /*DISP_WDMA1 */
					<GIC_SPI 199 IRQ_TYPE_LEVEL_LOW>, /*DISP_OVL0_2L*/
					<GIC_SPI 200 IRQ_TYPE_LEVEL_LOW>, /*DISP_OVL1_2L*/
					<GIC_SPI 0 IRQ_TYPE_LEVEL_LOW>; /*MIPITX0*/

			   clocks = <&mmsys MM_DISP0_SMI_COMMON>,
					<&mmsys MM_DISP0_SMI_LARB0>,
					<&mmsys MM_DISP0_DISP_OVL0>,
					<&mmsys MM_DISP0_DISP_OVL1>,
					<&mmsys MM_DISP0_DISP_RDMA0>,
					<&mmsys MM_DISP0_DISP_RDMA1>,
					<&mmsys MM_DISP0_DISP_WDMA0>,
					<&mmsys MM_DISP0_DISP_COLOR>,
					<&mmsys MM_DISP0_DISP_CCORR>,
					<&mmsys MM_DISP0_DISP_AAL>,
					<&mmsys MM_DISP0_DISP_GAMMA>,
					<&mmsys MM_DISP0_DISP_DITHER>,
					<&mmsys MM_DISP0_DISP_UFOE_MOUT>,
					<&mmsys MM_DISP0_DISP_WDMA1>,
					<&mmsys MM_DISP0_DISP_2L_OVL0>,
					<&mmsys MM_DISP0_DISP_2L_OVL1>,
					<&mmsys MM_DISP0_DISP_OVL0_MOUT>,
					<&mmsys MM_DISP1_DSI_ENGINE>,
					<&mmsys MM_DISP1_DSI_DIGITAL>,
					<&mmsys MM_DISP1_DPI_ENGINE>,
					<&mmsys MM_DISP1_DPI_PIXEL>,
					<&infrasys INFRA_DISP_PWM>,
					<&scpsys SCP_SYS_DIS>,
					<&topckgen TOP_MUX_DPI0>,
					<&topckgen TOP_TVDPLL_D2>,
					<&topckgen TOP_TVDPLL_D4>,
					<&topckgen TOP_TVDPLL_D8>,
					<&topckgen TOP_TVDPLL_D16>,
					<&topckgen TOP_DPI_CK>,
					<&topckgen TOP_MUX_DISPPWM>,
					<&topckgen TOP_UNIVPLL2_D4>,
					<&topckgen TOP_OSC_D2>,
					<&topckgen TOP_OSC_D8>;

		clock-names = "DISP0_SMI_COMMON",
					"DISP0_SMI_LARB0",
					"DISP0_DISP_OVL0",
					"DISP0_DISP_OVL1",
					"DISP0_DISP_RDMA0",
					"DISP0_DISP_RDMA1",
					"DISP0_DISP_WDMA0",
					"DISP0_DISP_COLOR",
					"DISP0_DISP_CCORR",
					"DISP0_DISP_AAL",
					"DISP0_DISP_GAMMA",
					"DISP0_DISP_DITHER",
					"DISP0_DISP_UFOE_MOUT",
					"DISP0_DISP_WDMA1",
					"DISP0_DISP_2L_OVL0",
					"DISP0_DISP_2L_OVL1",
					"DISP0_DISP_OVL0_MOUT",
					"DISP1_DSI_ENGINE",
					"DISP1_DSI_DIGITAL",
					"DISP1_DPI_ENGINE",
					"DISP1_DPI_PIXEL",
					"DISP_PWM",
					"DISP_MTCMOS_CLK",
					"MUX_DPI0",
					"TVDPLL_D2",
					"TVDPLL_D4",
					"TVDPLL_D8",
					"TVDPLL_D16",
					"DPI_CK",
					"MUX_PWM",
					"UNIVPLL2_D4",
					"OSC_D2",
					"OSC_D8";
		};

		disp_ovl0@14008000 {
			compatible = "mediatek,disp_ovl0";
			reg = <0x14008000 0x1000>;
			interrupts = <GIC_SPI 184 IRQ_TYPE_LEVEL_LOW>;
		};

		disp_ovl1@14009000 {
			compatible = "mediatek,disp_ovl1";
			reg = <0x14009000 0x1000>;
			interrupts = <GIC_SPI 185 IRQ_TYPE_LEVEL_LOW>;
		};

		disp_rdma0@1400a000 {
			compatible = "mediatek,disp_rdma0";
			reg = <0x1400a000 0x1000>;
			interrupts = <GIC_SPI 186 IRQ_TYPE_LEVEL_LOW>;
		};

		disp_rdma1@1400b000 {
			compatible = "mediatek,disp_rdma1";
			reg = <0x1400B000 0x1000>;
			interrupts = <GIC_SPI 187 IRQ_TYPE_LEVEL_LOW>;
		};

		disp_wdma0@1400c000 {
			compatible = "mediatek,disp_wdma0";
			reg = <0x1400c000 0x1000>;
			interrupts = <GIC_SPI 188 IRQ_TYPE_LEVEL_LOW>;
		};

		disp_color@1400d000 {
			compatible = "mediatek,disp_color";
			reg = <0x1400d000 0x1000>;
			interrupts = <GIC_SPI 189 IRQ_TYPE_LEVEL_LOW>;
		};

		disp_ccorr@1400e000 {
			compatible = "mediatek,disp_ccorr";
			reg = <0x1400e000 0x1000>;
			interrupts = <GIC_SPI 190 IRQ_TYPE_LEVEL_LOW>;
		};

		disp_aal@1400f000 {
			compatible = "mediatek,disp_aal";
			reg = <0x1400f000 0x1000>;
			interrupts = <GIC_SPI 191 IRQ_TYPE_LEVEL_LOW>;
		};

		disp_gamma@14010000 {
			compatible = "mediatek,disp_gamma";
			reg = <0x14010000 0x1000>;
			interrupts = <GIC_SPI 192 IRQ_TYPE_LEVEL_LOW>;
		};

		disp_dither@14011000 {
			compatible = "mediatek,disp_dither";
			reg = <0x14011000 0x1000>;
			interrupts = <GIC_SPI 193 IRQ_TYPE_LEVEL_LOW>;
		};

		dsi0@14012000 {
			compatible = "mediatek,dsi0";
			reg = <0x14012000 0x1000>;
			interrupts = <GIC_SPI 194 IRQ_TYPE_LEVEL_LOW>;
		};

		dpi0@14013000 {
			compatible = "mediatek,dpi0";
			reg = <0x14013000 0x1000>;
			interrupts = <GIC_SPI 195 IRQ_TYPE_LEVEL_LOW>;
		};

		mm_mutex@14014000 {
			compatible = "mediatek,mm_mutex";
			reg = <0x14014000 0x1000>;
			interrupts = <GIC_SPI 177 IRQ_TYPE_LEVEL_LOW>;
		};


		disp_wdma1@14017000 {
			compatible = "mediatek,disp_wdma1";
			reg = <0x14017000 0x1000>;
		};

		disp_ovl0_2l@14018000 {
			compatible = "mediatek,disp_ovl0_2l";
			reg = <0x14018000 0x1000>;
			interrupts = <GIC_SPI 199 IRQ_TYPE_LEVEL_LOW>;
		};

		disp_ovl1_2l@14019000 {
			compatible = "mediatek,disp_ovl1_2l";
			reg = <0x14019000 0x1000>;
			interrupts = <GIC_SPI 200 IRQ_TYPE_LEVEL_LOW>;
		};

		smi_larb0@14015000 {
			compatible = "mediatek,smi_larb0";
			reg = <0x14015000 0x1000>;
			interrupts = <GIC_SPI 201 IRQ_TYPE_LEVEL_LOW>;
		};

		met_smi: met_smi@14016000 {
			compatible = "mediatek,met_smi";
			reg = <0x14016000 0x1000>,  /* SMI_COMMON_EXT */
			    <0x14015000 0x1000>,  /* LARB 0 */
			    <0x16010000 0x10000>,  /* LARB 1 */
			    <0x15001000 0x1000>,  /* LARB 2 */
			    <0x17001000 0x1000>;  /* LARB 3 */

			clocks = <&mmsys MM_DISP0_SMI_COMMON>,
			       <&mmsys MM_DISP0_SMI_LARB0>,
			       <&imgsys IMG_IMAGE_LARB2_SMI>,
			       <&vdecsys VDEC0_VDEC>,
			       <&vdecsys VDEC1_LARB>,
			       <&vencsys VENC_LARB>,
			       <&vencsys VENC_VENC>;

			clock-names = "smi-common",
				"smi-larb0",
				"img-larb2",
				"vdec0-vdec",
				"vdec1-larb",
				"venc-larb",
				"venc-venc";
		};

		smi_common@14016000 {
			compatible = "mediatek,smi_common";
			reg = <0x14016000 0x1000>,	/* SMI_COMMON */
				<0x14015000 0x1000>,	/* LARB 0 */
				<0x16010000 0x10000>,	/* LARB 1 */
				<0x15001000 0x1000>,	/* LARB 2 */
				<0x17001000 0x1000>;	/* LARB 3 */
			clocks = <&mmsys MM_DISP0_SMI_COMMON>,
				<&mmsys MM_DISP0_SMI_LARB0>,
				<&imgsys IMG_IMAGE_LARB2_SMI>,
				<&vdecsys VDEC1_LARB>,
				<&vencsys VENC_VENC>,
				<&vencsys VENC_LARB>,
				<&scpsys SCP_SYS_VEN>,
				<&scpsys SCP_SYS_VDE>,
				<&scpsys SCP_SYS_ISP>,
				<&scpsys SCP_SYS_DIS>;
			clock-names = "smi-common", "smi-larb0", "img-larb2", "vdec1-larb", "venc-venc", "venc-larb",
			"mtcmos-ven", "mtcmos-vde", "mtcmos-isp", "mtcmos-dis";
		};

		imgsys: imgsys@15000000 {
			compatible = "mediatek,mt6755-imgsys";
			reg = <0x15000000 0x1000>;
			#clock-cells = <1>;
		};

		ispsys@15000000 {
			compatible = "mediatek,ispsys";
			reg = <0x15000000 0x10000>,  /*IMGSYS_CONFIG_ADDR      */
				<0x15004000 0x9000>,  /*ISP_ADDR      */
				<0x1500d000 0x1000>,  /*INNER_ISP_ADDR      */
				<0x10217000 0x3000>,  /*MIPI_ANA_ADDR      */
				<0x10002000 0x1000>;  /*GPIO_ADDR      */

			interrupts = <GIC_SPI 210 IRQ_TYPE_LEVEL_LOW>, /* CAM0 */
				<GIC_SPI 211 IRQ_TYPE_LEVEL_LOW>, /* CAM1 */
				<GIC_SPI 212 IRQ_TYPE_LEVEL_LOW>, /* CAM2 */
				<GIC_SPI 213 IRQ_TYPE_LEVEL_LOW>, /* CAMSV0 */
				<GIC_SPI 214 IRQ_TYPE_LEVEL_LOW>; /* CAMSV1 */

			clocks = <&scpsys SCP_SYS_DIS>,
				<&scpsys SCP_SYS_ISP>,
				<&mmsys MM_DISP0_SMI_COMMON>,
				<&imgsys IMG_IMAGE_CAM_SMI>,
				<&imgsys IMG_IMAGE_CAM_CAM>,
				<&imgsys IMG_IMAGE_SEN_TG>,
				<&imgsys IMG_IMAGE_SEN_CAM>,
				<&imgsys IMG_IMAGE_CAM_SV>,
				<&imgsys IMG_IMAGE_LARB2_SMI>;

			clock-names = "CG_SCP_SYS_DIS",
				"CG_SCP_SYS_ISP",
				"CG_DISP0_SMI_COMMON",
				"CG_IMAGE_CAM_SMI",
				"CG_IMAGE_CAM_CAM",
				"CG_IMAGE_SEN_TG",
				"CG_IMAGE_SEN_CAM",
				"CG_IMAGE_CAM_SV",
				"CG_IMAGE_LARB2_SMI";
		};

		smi_larb2@15001000 {
			compatible = "mediatek,smi_larb2";
			reg = <0x15001000 0x1000>;
			interrupts = <GIC_SPI 208 IRQ_TYPE_LEVEL_LOW>;
		};

		cam0@15004000 {
			compatible = "mediatek,cam0";
			reg = <0x15004000 0x1000>;
		};

		cam1@15005000 {
			compatible = "mediatek,cam1";
			reg = <0x15005000 0x1000>;
			interrupts = <GIC_SPI 210 IRQ_TYPE_LEVEL_LOW>;
		};

		cam2@15006000 {
			compatible = "mediatek,cam2";
			reg = <0x15006000 0x1000>;
			interrupts = <GIC_SPI 211 IRQ_TYPE_LEVEL_LOW>;
		};

		cam3@15007000 {
			compatible = "mediatek,cam3";
			reg = <0x15007000 0x1000>;
			interrupts = <GIC_SPI 212 IRQ_TYPE_LEVEL_LOW>;
		};

		kd_camera_hw1:kd_camera_hw1@15008000 {
			compatible = "mediatek,camera_hw";
			reg = <0x15008000 0x1000>;  /* SENINF_ADDR */

			/* Camera Common Clock Framework (CCF) */
			clocks = <&topckgen TOP_MUX_CAMTG>,
			<&topckgen TOP_MUX_SCAM>,
			<&topckgen TOP_UNIVPLL_D26>,
			<&topckgen TOP_UNIVPLL2_D2>;
			clock-names = "TOP_CAMTG_SEL","TOP_MUX_SCAM","TOP_UNIVPLL_D26","TOP_UNIVPLL2_D2";
			vcama-supply = <&mt_pmic_vcama_ldo_reg>;
			vcamd-supply = <&mt_pmic_vcamd_ldo_reg>;
			vcamio-supply = <&mt_pmic_vcamio_ldo_reg>;
		};

		kd_camera_hw2:kd_camera_hw2@15008000 {
			compatible = "mediatek,camera_hw2";
			reg = <0x15008000 0x1000>;  /* SENINF_ADDR */
		};

		seninf@15008000 {
			compatible = "mediatek,seninf";
			reg = <0x15008000 0x1000>;
			interrupts = <GIC_SPI 209 IRQ_TYPE_LEVEL_LOW>;
		};

		camsv@15009000 {
			compatible = "mediatek,camsv";
			reg = <0x15009000 0x1000>;
			interrupts = <GIC_SPI 213 IRQ_TYPE_LEVEL_LOW>;
		};

		fdvt@1500b000 {
			compatible = "mediatek,fdvt";
			reg = <0x1500b000 0x1000>;
			interrupts = <GIC_SPI 215 IRQ_TYPE_LEVEL_LOW>;
			clocks = <&scpsys SCP_SYS_DIS>,
					<&scpsys SCP_SYS_ISP>,
					<&mmsys MM_DISP0_SMI_COMMON_FDVT>,
					<&imgsys IMG_IMAGE_FD>;
			clock-names = "FD-SCP_SYS_DIS",
						"FD-SCP_SYS_ISP",
						"FD-MM_DISP0_SMI_COMMON",
						"FD-IMG_IMAGE_FD";
		};

		mipi_rx@1500c000 {
			compatible = "mediatek,mipi_rx";
			reg = <0x1500c000 0x1000>;
		};

		cam0_inner@1500d000 {
			compatible = "mediatek,cam0_inner";
			reg = <0x1500d000 0x1000>;
		};

		cam2_inner@1500e000 {
			compatible = "mediatek,cam2_inner";
			reg = <0x1500e000 0x1000>;
		};

		cam3_inner@1500f000 {
			compatible = "mediatek,cam3_inner";
			reg = <0x1500f000 0x1000>;
		};

		vdecsys: vdec_gcon@16000000 {
			compatible = "mediatek,mt6755-vdec_gcon", "mediatek,mt6755-vdecsys";
			reg = <0x16000000 0x1000>;
			interrupts = <GIC_SPI 206 IRQ_TYPE_LEVEL_LOW>;
			clocks = <&mmsys MM_DISP0_SMI_COMMON>, <&vdecsys VDEC0_VDEC>,
					<&vdecsys VDEC1_LARB>, <&vencsys VENC_VENC>,
					<&vencsys VENC_LARB>, <&topckgen TOP_MUX_VDEC>,
					<&topckgen TOP_SYSPLL1_D2>, <&topckgen TOP_SYSPLL1_D4>,
					<&scpsys SCP_SYS_VDE>, <&scpsys SCP_SYS_VEN>, <&scpsys SCP_SYS_DIS>;
			clock-names = "MT_CG_DISP0_SMI_COMMON", "MT_CG_VDEC0_VDEC",
					"MT_CG_VDEC1_LARB", "MT_CG_VENC_VENC",
					"MT_CG_VENC_LARB", "MT_CG_TOP_MUX_VDEC",
					"MT_CG_TOP_SYSPLL1_D2", "MT_CG_TOP_SYSPLL1_D4",
					"MT_SCP_SYS_VDE", "MT_SCP_SYS_VEN", "MT_SCP_SYS_DIS";
			#clock-cells = <1>;
		};

		smi_larb1@16010000 {
			compatible = "mediatek,smi_larb1";
			reg = <0x16010000 0x10000>;
			interrupts = <GIC_SPI 207 IRQ_TYPE_LEVEL_LOW>;
		};

		vdec_full_top: vdec_full_top@16020000 {
			compatible = "mediatek,mt6755-vdec_full_top";
			reg = <0x16020000 0x10000>;
			interrupts = <GIC_SPI 206 IRQ_TYPE_LEVEL_LOW>;
		};

		vencsys: venc_gcon@17000000 {
			compatible = "mediatek,mt6755-venc_gcon", "mediatek,mt6755-vencsys";
			reg = <0x17000000 0x1000>;
			interrupts = <GIC_SPI 202 IRQ_TYPE_LEVEL_LOW>;
			#clock-cells = <1>;
		};

		smi_larb3@17001000 {
			compatible = "mediatek,smi_larb3";
			reg = <0x17001000 0x1000>;
			interrupts = <GIC_SPI 203 IRQ_TYPE_LEVEL_LOW>;
		};

		venc: venc@17002000 {
			compatible = "mediatek,mt6755-venc";
			reg = <0x17002000 0x1000>;
			interrupts = <GIC_SPI 202 IRQ_TYPE_LEVEL_LOW>;
		};

		jpgenc@17003000 {
			compatible = "mediatek,jpgenc";
			reg = <0x17003000 0x1000>;
			interrupts = <GIC_SPI 204 IRQ_TYPE_LEVEL_LOW>;
			clocks = <&scpsys SCP_SYS_DIS>,
				<&mmsys MM_DISP0_SMI_COMMON>,
				<&scpsys SCP_SYS_VEN>,
				<&vencsys VENC_LARB>,
				<&vencsys VENC_JPGENC>;

			clock-names = "disp-mtcmos",
				"disp-smi",
				"venc-mtcmos",
				"venc-larb",
				"venc-jpgenc";
		};

		jpgdec@17004000 {
			compatible = "mediatek,jpgdec";
			reg = <0x17004000 0x1000>;
			interrupts = <GIC_SPI 205 IRQ_TYPE_LEVEL_LOW>;
			clocks = <&scpsys SCP_SYS_DIS>,
				<&mmsys MM_DISP0_SMI_COMMON>,
				<&scpsys SCP_SYS_VEN>,
				<&vencsys VENC_LARB>,
				<&vencsys VENC_JPGDEC>;

			clock-names = "disp-mtcmos",
					"disp-smi",
					"venc-mtcmos",
					"venc-larb",
					"venc-jpgdec";
		};

		btcvsd@18000000 {
			compatible = "mediatek,audio_bt_cvsd";
			offset =<0xF00 0x800 0xFD0 0xFD4 0xFD8>;
			/*INFRA MISC, conn_bt_cvsd_mask, cvsd_mcu_read, write, packet_indicator*/
			reg=<0x10001000 0x1000>, /*AUDIO_INFRA_BASE_PHYSICAL*/
			      <0x18000000 0x10000>, /*PKV_PHYSICAL_BASE*/
			      <0x18080000 0x8000>; /*SRAM_BANK2*/
		  interrupts = <GIC_SPI 236 IRQ_TYPE_LEVEL_LOW>;
		};

		consys:consys@18070000 {
			compatible = "mediatek,mt6755-consys";
			reg = <0x18070000 0x0200>,  /*CONN_MCU_CONFIG_BASE */
			      <0x10007000 0x0100>,  /*AP_RGU_BASE */
			      <0x10000000 0x2000>,  /*TOPCKGEN_BASE */
			      <0x10006000 0x1000>;  /*SPM_BASE */
			interrupts = <GIC_SPI 237 IRQ_TYPE_LEVEL_LOW>, /*BGF_EINT */
					<GIC_SPI 239 IRQ_TYPE_LEVEL_LOW>; /*WDT_EINT */
			clocks = <&scpsys SCP_SYS_CONN>;
			clock-names = "conn";
			/* vcn18-supply = <&mt_pmic_vcn18_ldo_reg>;
			vcn28-supply = <&mt_pmic_vcn28_ldo_reg>;
			vcn33_bt-supply = <&mt_pmic_vcn33_bt_ldo_reg>;
			vcn33_wifi-supply = <&mt_pmic_vcn33_wifi_ldo_reg>; */
		};

		wifi@180f0000 {
			compatible = "mediatek,wifi";
			reg = <0x180f0000 0x005c>;
			interrupts = <GIC_SPI 238 IRQ_TYPE_LEVEL_LOW>;
		};

		ccci_off@0 {
			compatible = "mediatek,ccci_off";
			clocks = <&scpsys SCP_SYS_MD1>;
			clock-names = "scp-sys-md1-main";
		};

		gps {
			compatible = "mediatek,gps";
		};

		accdet: accdet@ {
			compatible = "mediatek,mt6755-accdet";
		};

		gsensor@0 {
			compatible = "mediatek,gsensor";
			/* vgsensor-supply = <&mt_pmic_vio28_ldo_reg>; */
		};

		alsps:als_ps@0 {
			compatible = "mediatek,als_ps";
			/* valsps-supply = <&mt_pmic_vio28_ldo_reg>; */
		};

		gyroscope:gyroscope@0 {
			compatible = "mediatek,gyroscope";
			/* vgyro-supply = <&mt_pmic_vio28_ldo_reg>; */
		};

		barometer@0 {
			compatible = "mediatek,barometer";
			/* vbarometer-supply = <&mt_pmic_vio28_ldo_reg>; */
		};

		m_baro_pl@0 {
			compatible = "mediatek,m_baro_pl";
			/* vbarometer-supply = <&mt_pmic_vio28_ldo_reg>; */
		};

		msensor@0 {
			compatible = "mediatek,msensor";
			/* vmsensor-supply = <&mt_pmic_vio28_ldo_reg>; */
		};

		mtkfb@0 {
			compatible = "mediatek,mtkfb";
		};

		touch: touch {
			compatible = "mediatek,mt6755-touch";
			/* VTOUCH-supply = <&mt_pmic_vgp1_ldo_reg>; */
		};

		psci {
			compatible  = "arm,psci";
			method      = "smc";
			cpu_suspend = <0x84000001>;
			cpu_off     = <0x84000002>;
			cpu_on      = <0x84000003>;
			affinity_info = <0x84000004>;
		};

	};

	mobicore {
		compatible = "trustonic,mobicore";
		interrupts = <GIC_SPI 248 IRQ_TYPE_EDGE_RISING>;
	};

	/* Add dummy nodes for cust.dtsi */
	als: als {
		compatible = "mediatek, als-eint";
		status = "disabled";
	};

	gse_1: gse_1 {
		compatible = "mediatek, gse_1-eint";
		status = "disabled";
	};

	ext_buck_oc: ext_buck_oc {
		compatible = "mediatek, ext_buck_oc-eint";
		status = "disabled";
	};

	msdc1_ins: msdc1_ins {
		compatible = "mediatek, msdc1_ins-eint";
		status = "disabled";
	};

	gyro: gyro {
		compatible = "mediatek, gyro-eint";
		status = "disabled";
	};

	mse: mse {
		compatible = "mediatek, mse-eint";
		status = "disabled";
	};

	mrdump_ext_rst: mrdump_ext_rst {
		compatible = "mediatek, mrdump_ext_rst-eint";
		status = "disabled";
	};

	irq_nfc: irq_nfc {
		compatible = "mediatek, irq_nfc-eint";
		status = "disabled";
	};

	dsi_te: dsi_te {
		compatible = "mediatek, dsi_te-eint";
		status = "disabled";
	};


	auxadc: auxadc {
		compatible = "mediatek, auxadc";
		status = "disabled";
	};

	rf_clock_buffer_ctrl:rf_clock_buffer {
		compatible = "mediatek,rf_clock_buffer";
		mediatek,clkbuf-quantity = <4>;
		mediatek,clkbuf-config = <2 0 1 1>;
		mediatek,clkbuf-driving-current = <2 2 2 2>;
	};

	pmic_clock_buffer_ctrl:pmic_clock_buffer {
		compatible = "mediatek,pmic_clock_buffer";
		mediatek,clkbuf-quantity = <4>;
		mediatek,clkbuf-config = <2 1 1 2>;
		mediatek,clkbuf-driving-current = <2 2 2 2>;
	};
};
/*/include/ "cust_pmic.dtsi"*/

#include "cust_mt6755_msdc.dtsi"

#include <trusty.dtsi>
